VERSION "1.0"

NS_ :

BS_:

BU_: PC DASHBOARD PDM_FRONT PDM_REAR KEYPAD

BO_ 1536 CMD_BROADCAST: 8 PC
 SG_ MsgType M : 0|8@1+ (1,0) [0|255] "" Vector__XXX

BO_ 1605 CMD_DASHBOARD: 8 PC
 SG_ MsgType M : 0|8@1+ (1,0) [0|255] "" DASHBOARD
 SG_ FileSize m16 : 8|32@1+ (1,0) [0|4294967295] "bytes" DASHBOARD
 SG_ FileCrc32 m17 : 8|32@1+ (1,0) [0|4294967295] "" DASHBOARD
 SG_ BlockNumber m18 : 8|16@1+ (1,0) [0|65535] "" DASHBOARD
 SG_ BlockLength m18 : 24|16@1+ (1,0) [0|65535] "bytes" DASHBOARD

BO_ 1733 REPLY_DASHBOARD: 8 DASHBOARD
 SG_ MsgType M : 0|8@1+ (1,0) [0|255] "" PC
 SG_ HbState m128 : 8|8@1+ (1,0) [0|255] "" PC
 SG_ HbFwMajor m128 : 16|8@1+ (1,0) [0|255] "" PC
 SG_ HbFwMinor m128 : 24|8@1+ (1,0) [0|255] "" PC
 SG_ HbFwPatch m128 : 32|8@1+ (1,0) [0|255] "" PC
 SG_ ChipType m129 : 8|8@1+ (1,0) [0|255] "" PC
 SG_ HwRevision m129 : 16|8@1+ (1,0) [0|255] "" PC
 SG_ FwMajor m129 : 24|8@1+ (1,0) [0|255] "" PC
 SG_ FwMinor m129 : 32|8@1+ (1,0) [0|255] "" PC
 SG_ FwPatch m129 : 40|8@1+ (1,0) [0|255] "" PC
 SG_ Uid0 m130 : 8|8@1+ (1,0) [0|255] "" PC
 SG_ Uid1 m130 : 16|8@1+ (1,0) [0|255] "" PC
 SG_ Uid2 m130 : 24|8@1+ (1,0) [0|255] "" PC
 SG_ Uid3 m130 : 32|8@1+ (1,0) [0|255] "" PC
 SG_ Uid4 m130 : 40|8@1+ (1,0) [0|255] "" PC
 SG_ Uid5 m130 : 48|8@1+ (1,0) [0|255] "" PC
 SG_ BeginStatus m144 : 8|8@1+ (1,0) [0|255] "" PC
 SG_ AckBlock m146 : 8|16@1+ (1,0) [0|65535] "" PC
 SG_ AckStatus m146 : 24|8@1+ (1,0) [0|255] "" PC
 SG_ FinishStatus m147 : 8|8@1+ (1,0) [0|255] "" PC
 SG_ BootStatus m149 : 8|8@1+ (1,0) [0|255] "" PC

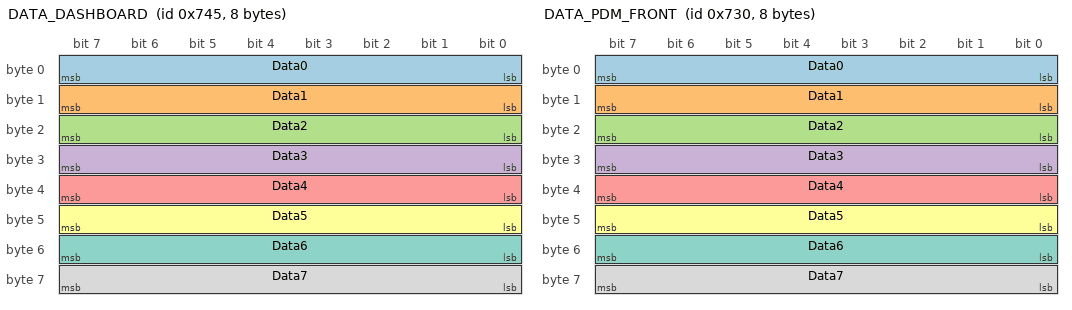
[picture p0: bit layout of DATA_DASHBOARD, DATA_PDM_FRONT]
BO_ 1861 DATA_DASHBOARD: 8 PC
 SG_ Data0 : 0|8@1+ (1,0) [0|255] "" DASHBOARD
 SG_ Data1 : 8|8@1+ (1,0) [0|255] "" DASHBOARD
 SG_ Data2 : 16|8@1+ (1,0) [0|255] "" DASHBOARD
 SG_ Data3 : 24|8@1+ (1,0) [0|255] "" DASHBOARD
 SG_ Data4 : 32|8@1+ (1,0) [0|255] "" DASHBOARD
 SG_ Data5 : 40|8@1+ (1,0) [0|255] "" DASHBOARD
 SG_ Data6 : 48|8@1+ (1,0) [0|255] "" DASHBOARD
 SG_ Data7 : 56|8@1+ (1,0) [0|255] "" DASHBOARD

BO_ 1584 CMD_PDM_FRONT: 8 PC
 SG_ MsgType M : 0|8@1+ (1,0) [0|255] "" PDM_FRONT
 SG_ FileSize m16 : 8|32@1+ (1,0) [0|4294967295] "bytes" PDM_FRONT
 SG_ FileCrc32 m17 : 8|32@1+ (1,0) [0|4294967295] "" PDM_FRONT
 SG_ BlockNumber m18 : 8|16@1+ (1,0) [0|65535] "" PDM_FRONT
 SG_ BlockLength m18 : 24|16@1+ (1,0) [0|65535] "bytes" PDM_FRONT

BO_ 1712 REPLY_PDM_FRONT: 8 PDM_FRONT
 SG_ MsgType M : 0|8@1+ (1,0) [0|255] "" PC
 SG_ HbState m128 : 8|8@1+ (1,0) [0|255] "" PC
 SG_ HbFwMajor m128 : 16|8@1+ (1,0) [0|255] "" PC
 SG_ HbFwMinor m128 : 24|8@1+ (1,0) [0|255] "" PC
 SG_ HbFwPatch m128 : 32|8@1+ (1,0) [0|255] "" PC
 SG_ ChipType m129 : 8|8@1+ (1,0) [0|255] "" PC
 SG_ HwRevision m129 : 16|8@1+ (1,0) [0|255] "" PC
 SG_ FwMajor m129 : 24|8@1+ (1,0) [0|255] "" PC
 SG_ FwMinor m129 : 32|8@1+ (1,0) [0|255] "" PC
 SG_ FwPatch m129 : 40|8@1+ (1,0) [0|255] "" PC
 SG_ Uid0 m130 : 8|8@1+ (1,0) [0|255] "" PC
 SG_ Uid1 m130 : 16|8@1+ (1,0) [0|255] "" PC
 SG_ Uid2 m130 : 24|8@1+ (1,0) [0|255] "" PC
 SG_ Uid3 m130 : 32|8@1+ (1,0) [0|255] "" PC
 SG_ Uid4 m130 : 40|8@1+ (1,0) [0|255] "" PC
 SG_ Uid5 m130 : 48|8@1+ (1,0) [0|255] "" PC
 SG_ BeginStatus m144 : 8|8@1+ (1,0) [0|255] "" PC
 SG_ AckBlock m146 : 8|16@1+ (1,0) [0|65535] "" PC
 SG_ AckStatus m146 : 24|8@1+ (1,0) [0|255] "" PC
 SG_ FinishStatus m147 : 8|8@1+ (1,0) [0|255] "" PC
 SG_ BootStatus m149 : 8|8@1+ (1,0) [0|255] "" PC

BO_ 1840 DATA_PDM_FRONT: 8 PC
 SG_ Data0 : 0|8@1+ (1,0) [0|255] "" PDM_FRONT
 SG_ Data1 : 8|8@1+ (1,0) [0|255] "" PDM_FRONT
 SG_ Data2 : 16|8@1+ (1,0) [0|255] "" PDM_FRONT
 SG_ Data3 : 24|8@1+ (1,0) [0|255] "" PDM_FRONT
 SG_ Data4 : 32|8@1+ (1,0) [0|255] "" PDM_FRONT
 SG_ Data5 : 40|8@1+ (1,0) [0|255] "" PDM_FRONT
 SG_ Data6 : 48|8@1+ (1,0) [0|255] "" PDM_FRONT
 SG_ Data7 : 56|8@1+ (1,0) [0|255] "" PDM_FRONT

BO_ 1585 CMD_PDM_REAR: 8 PC
 SG_ MsgType M : 0|8@1+ (1,0) [0|255] "" PDM_REAR
 SG_ FileSize m16 : 8|32@1+ (1,0) [0|4294967295] "bytes" PDM_REAR
 SG_ FileCrc32 m17 : 8|32@1+ (1,0) [0|4294967295] "" PDM_REAR
 SG_ BlockNumber m18 : 8|16@1+ (1,0) [0|65535] "" PDM_REAR
 SG_ BlockLength m18 : 24|16@1+ (1,0) [0|65535] "bytes" PDM_REAR

BO_ 1713 REPLY_PDM_REAR: 8 PDM_REAR
 SG_ MsgType M : 0|8@1+ (1,0) [0|255] "" PC
 SG_ HbState m128 : 8|8@1+ (1,0) [0|255] "" PC
 SG_ HbFwMajor m128 : 16|8@1+ (1,0) [0|255] "" PC
 SG_ HbFwMinor m128 : 24|8@1+ (1,0) [0|255] "" PC
 SG_ HbFwPatch m128 : 32|8@1+ (1,0) [0|255] "" PC
 SG_ ChipType m129 : 8|8@1+ (1,0) [0|255] "" PC
 SG_ HwRevision m129 : 16|8@1+ (1,0) [0|255] "" PC
 SG_ FwMajor m129 : 24|8@1+ (1,0) [0|255] "" PC
 SG_ FwMinor m129 : 32|8@1+ (1,0) [0|255] "" PC
 SG_ FwPatch m129 : 40|8@1+ (1,0) [0|255] "" PC
 SG_ Uid0 m130 : 8|8@1+ (1,0) [0|255] "" PC
 SG_ Uid1 m130 : 16|8@1+ (1,0) [0|255] "" PC
 SG_ Uid2 m130 : 24|8@1+ (1,0) [0|255] "" PC
 SG_ Uid3 m130 : 32|8@1+ (1,0) [0|255] "" PC
 SG_ Uid4 m130 : 40|8@1+ (1,0) [0|255] "" PC
 SG_ Uid5 m130 : 48|8@1+ (1,0) [0|255] "" PC
 SG_ BeginStatus m144 : 8|8@1+ (1,0) [0|255] "" PC
 SG_ AckBlock m146 : 8|16@1+ (1,0) [0|65535] "" PC
 SG_ AckStatus m146 : 24|8@1+ (1,0) [0|255] "" PC
 SG_ FinishStatus m147 : 8|8@1+ (1,0) [0|255] "" PC
 SG_ BootStatus m149 : 8|8@1+ (1,0) [0|255] "" PC

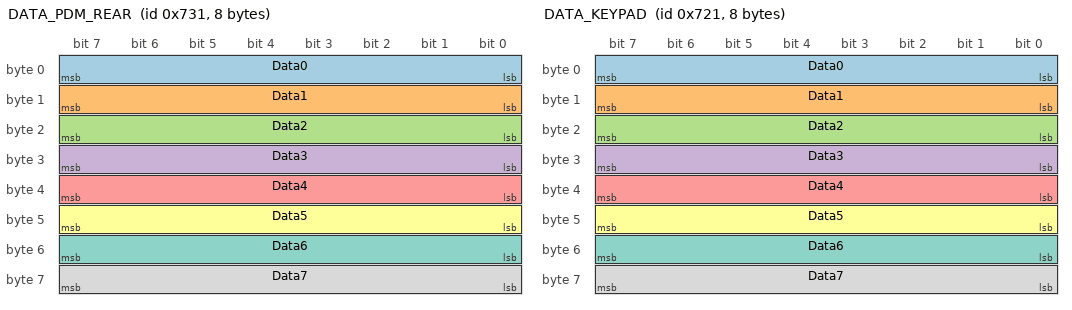
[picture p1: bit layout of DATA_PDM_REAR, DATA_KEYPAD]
BO_ 1841 DATA_PDM_REAR: 8 PC
 SG_ Data0 : 0|8@1+ (1,0) [0|255] "" PDM_REAR
 SG_ Data1 : 8|8@1+ (1,0) [0|255] "" PDM_REAR
 SG_ Data2 : 16|8@1+ (1,0) [0|255] "" PDM_REAR
 SG_ Data3 : 24|8@1+ (1,0) [0|255] "" PDM_REAR
 SG_ Data4 : 32|8@1+ (1,0) [0|255] "" PDM_REAR
 SG_ Data5 : 40|8@1+ (1,0) [0|255] "" PDM_REAR
 SG_ Data6 : 48|8@1+ (1,0) [0|255] "" PDM_REAR
 SG_ Data7 : 56|8@1+ (1,0) [0|255] "" PDM_REAR

BO_ 1569 CMD_KEYPAD: 8 PC
 SG_ MsgType M : 0|8@1+ (1,0) [0|255] "" KEYPAD
 SG_ FileSize m16 : 8|32@1+ (1,0) [0|4294967295] "bytes" KEYPAD
 SG_ FileCrc32 m17 : 8|32@1+ (1,0) [0|4294967295] "" KEYPAD
 SG_ BlockNumber m18 : 8|16@1+ (1,0) [0|65535] "" KEYPAD
 SG_ BlockLength m18 : 24|16@1+ (1,0) [0|65535] "bytes" KEYPAD

BO_ 1697 REPLY_KEYPAD: 8 KEYPAD
 SG_ MsgType M : 0|8@1+ (1,0) [0|255] "" PC
 SG_ HbState m128 : 8|8@1+ (1,0) [0|255] "" PC
 SG_ HbFwMajor m128 : 16|8@1+ (1,0) [0|255] "" PC
 SG_ HbFwMinor m128 : 24|8@1+ (1,0) [0|255] "" PC
 SG_ HbFwPatch m128 : 32|8@1+ (1,0) [0|255] "" PC
 SG_ ChipType m129 : 8|8@1+ (1,0) [0|255] "" PC
 SG_ HwRevision m129 : 16|8@1+ (1,0) [0|255] "" PC
 SG_ FwMajor m129 : 24|8@1+ (1,0) [0|255] "" PC
 SG_ FwMinor m129 : 32|8@1+ (1,0) [0|255] "" PC
 SG_ FwPatch m129 : 40|8@1+ (1,0) [0|255] "" PC
 SG_ Uid0 m130 : 8|8@1+ (1,0) [0|255] "" PC
 SG_ Uid1 m130 : 16|8@1+ (1,0) [0|255] "" PC
 SG_ Uid2 m130 : 24|8@1+ (1,0) [0|255] "" PC
 SG_ Uid3 m130 : 32|8@1+ (1,0) [0|255] "" PC
 SG_ Uid4 m130 : 40|8@1+ (1,0) [0|255] "" PC
 SG_ Uid5 m130 : 48|8@1+ (1,0) [0|255] "" PC
 SG_ BeginStatus m144 : 8|8@1+ (1,0) [0|255] "" PC
 SG_ AckBlock m146 : 8|16@1+ (1,0) [0|65535] "" PC
 SG_ AckStatus m146 : 24|8@1+ (1,0) [0|255] "" PC
 SG_ FinishStatus m147 : 8|8@1+ (1,0) [0|255] "" PC
 SG_ BootStatus m149 : 8|8@1+ (1,0) [0|255] "" PC

BO_ 1825 DATA_KEYPAD: 8 PC
 SG_ Data0 : 0|8@1+ (1,0) [0|255] "" KEYPAD
 SG_ Data1 : 8|8@1+ (1,0) [0|255] "" KEYPAD
 SG_ Data2 : 16|8@1+ (1,0) [0|255] "" KEYPAD
 SG_ Data3 : 24|8@1+ (1,0) [0|255] "" KEYPAD
 SG_ Data4 : 32|8@1+ (1,0) [0|255] "" KEYPAD
 SG_ Data5 : 40|8@1+ (1,0) [0|255] "" KEYPAD
 SG_ Data6 : 48|8@1+ (1,0) [0|255] "" KEYPAD
 SG_ Data7 : 56|8@1+ (1,0) [0|255] "" KEYPAD

CM_ BO_ 1536 "PC to all boards. Only SCAN (MsgType 1) is accepted in broadcast.";
CM_ BO_ 1605 "PC to Dashboard (ESP32-S3): commands. MsgType 1 SCAN, 16 BEGIN, 17 CRC, 18 BLOCK_END, 19 FINISH, 20 ABORT, 21 ENTER_BOOT.";
CM_ BO_ 1733 "Dashboard (ESP32-S3) to PC: heartbeat, scan answers (INFO_A, INFO_B) and update answers.";
CM_ SG_ 1733 HwRevision "Hardware revision as an ASCII letter (65 = A, 66 = B).";
CM_ SG_ 1733 AckBlock "Number of the block confirmed (or refused) by the board.";
CM_ BO_ 1861 "File data for Dashboard (ESP32-S3): 8 raw bytes per frame, 32 frames per block of 256 bytes.";
CM_ BO_ 1584 "PC to PDM Anteriore (STM32): commands. MsgType 1 SCAN, 16 BEGIN, 17 CRC, 18 BLOCK_END, 19 FINISH, 20 ABORT, 21 ENTER_BOOT.";
CM_ BO_ 1712 "PDM Anteriore (STM32) to PC: heartbeat, scan answers (INFO_A, INFO_B) and update answers.";
CM_ SG_ 1712 HwRevision "Hardware revision as an ASCII letter (65 = A, 66 = B).";
CM_ SG_ 1712 AckBlock "Number of the block confirmed (or refused) by the board.";
CM_ BO_ 1840 "File data for PDM Anteriore (STM32): 8 raw bytes per frame, 32 frames per block of 256 bytes.";
CM_ BO_ 1585 "PC to PDM Posteriore (STM32): commands. MsgType 1 SCAN, 16 BEGIN, 17 CRC, 18 BLOCK_END, 19 FINISH, 20 ABORT, 21 ENTER_BOOT.";
CM_ BO_ 1713 "PDM Posteriore (STM32) to PC: heartbeat, scan answers (INFO_A, INFO_B) and update answers.";
CM_ SG_ 1713 HwRevision "Hardware revision as an ASCII letter (65 = A, 66 = B).";
CM_ SG_ 1713 AckBlock "Number of the block confirmed (or refused) by the board.";
CM_ BO_ 1841 "File data for PDM Posteriore (STM32): 8 raw bytes per frame, 32 frames per block of 256 bytes.";
CM_ BO_ 1569 "PC to Tastierino: commands. MsgType 1 SCAN, 16 BEGIN, 17 CRC, 18 BLOCK_END, 19 FINISH, 20 ABORT, 21 ENTER_BOOT.";
CM_ BO_ 1697 "Tastierino to PC: heartbeat, scan answers (INFO_A, INFO_B) and update answers.";
CM_ SG_ 1697 HwRevision "Hardware revision as an ASCII letter (65 = A, 66 = B).";
CM_ SG_ 1697 AckBlock "Number of the block confirmed (or refused) by the board.";
CM_ BO_ 1825 "File data for Tastierino: 8 raw bytes per frame, 32 frames per block of 256 bytes.";

VAL_ 1536 MsgType 1 "SCAN" ;
VAL_ 1605 MsgType 1 "SCAN" 16 "BEGIN" 17 "CRC" 18 "BLOCK_END" 19 "FINISH" 20 "ABORT" 21 "ENTER_BOOT" ;
VAL_ 1733 MsgType 128 "HEARTBEAT" 129 "INFO_A" 130 "INFO_B" 144 "BEGIN_ACK" 146 "BLOCK_ACK" 147 "FINISH_ACK" 149 "BOOT_ACK" ;
VAL_ 1733 HbState 0 "APPLICATION" 1 "UPDATE_IN_PROGRESS" ;
VAL_ 1733 ChipType 1 "ESP32-S3" 2 "STM32" ;
VAL_ 1733 BeginStatus 0 "OK" 1 "RETRY" 2 "TOO_BIG" 3 "BUSY" 4 "FLASH_ERROR" 5 "INVALID" ;
VAL_ 1733 AckStatus 0 "OK" 1 "RETRY" 2 "TOO_BIG" 3 "BUSY" 4 "FLASH_ERROR" 5 "INVALID" ;
VAL_ 1733 FinishStatus 0 "OK" 1 "RETRY" 2 "TOO_BIG" 3 "BUSY" 4 "FLASH_ERROR" 5 "INVALID" ;
VAL_ 1733 BootStatus 0 "OK" 1 "RETRY" 2 "TOO_BIG" 3 "BUSY" 4 "FLASH_ERROR" 5 "INVALID" ;
VAL_ 1584 MsgType 1 "SCAN" 16 "BEGIN" 17 "CRC" 18 "BLOCK_END" 19 "FINISH" 20 "ABORT" 21 "ENTER_BOOT" ;
VAL_ 1712 MsgType 128 "HEARTBEAT" 129 "INFO_A" 130 "INFO_B" 144 "BEGIN_ACK" 146 "BLOCK_ACK" 147 "FINISH_ACK" 149 "BOOT_ACK" ;
VAL_ 1712 HbState 0 "APPLICATION" 1 "UPDATE_IN_PROGRESS" ;
VAL_ 1712 ChipType 1 "ESP32-S3" 2 "STM32" ;
VAL_ 1712 BeginStatus 0 "OK" 1 "RETRY" 2 "TOO_BIG" 3 "BUSY" 4 "FLASH_ERROR" 5 "INVALID" ;
VAL_ 1712 AckStatus 0 "OK" 1 "RETRY" 2 "TOO_BIG" 3 "BUSY" 4 "FLASH_ERROR" 5 "INVALID" ;
VAL_ 1712 FinishStatus 0 "OK" 1 "RETRY" 2 "TOO_BIG" 3 "BUSY" 4 "FLASH_ERROR" 5 "INVALID" ;
VAL_ 1712 BootStatus 0 "OK" 1 "RETRY" 2 "TOO_BIG" 3 "BUSY" 4 "FLASH_ERROR" 5 "INVALID" ;
VAL_ 1585 MsgType 1 "SCAN" 16 "BEGIN" 17 "CRC" 18 "BLOCK_END" 19 "FINISH" 20 "ABORT" 21 "ENTER_BOOT" ;
VAL_ 1713 MsgType 128 "HEARTBEAT" 129 "INFO_A" 130 "INFO_B" 144 "BEGIN_ACK" 146 "BLOCK_ACK" 147 "FINISH_ACK" 149 "BOOT_ACK" ;
VAL_ 1713 HbState 0 "APPLICATION" 1 "UPDATE_IN_PROGRESS" ;
VAL_ 1713 ChipType 1 "ESP32-S3" 2 "STM32" ;
VAL_ 1713 BeginStatus 0 "OK" 1 "RETRY" 2 "TOO_BIG" 3 "BUSY" 4 "FLASH_ERROR" 5 "INVALID" ;
VAL_ 1713 AckStatus 0 "OK" 1 "RETRY" 2 "TOO_BIG" 3 "BUSY" 4 "FLASH_ERROR" 5 "INVALID" ;
VAL_ 1713 FinishStatus 0 "OK" 1 "RETRY" 2 "TOO_BIG" 3 "BUSY" 4 "FLASH_ERROR" 5 "INVALID" ;
VAL_ 1713 BootStatus 0 "OK" 1 "RETRY" 2 "TOO_BIG" 3 "BUSY" 4 "FLASH_ERROR" 5 "INVALID" ;
VAL_ 1569 MsgType 1 "SCAN" 16 "BEGIN" 17 "CRC" 18 "BLOCK_END" 19 "FINISH" 20 "ABORT" 21 "ENTER_BOOT" ;
VAL_ 1697 MsgType 128 "HEARTBEAT" 129 "INFO_A" 130 "INFO_B" 144 "BEGIN_ACK" 146 "BLOCK_ACK" 147 "FINISH_ACK" 149 "BOOT_ACK" ;
VAL_ 1697 HbState 0 "APPLICATION" 1 "UPDATE_IN_PROGRESS" ;
VAL_ 1697 ChipType 1 "ESP32-S3" 2 "STM32" ;
VAL_ 1697 BeginStatus 0 "OK" 1 "RETRY" 2 "TOO_BIG" 3 "BUSY" 4 "FLASH_ERROR" 5 "INVALID" ;
VAL_ 1697 AckStatus 0 "OK" 1 "RETRY" 2 "TOO_BIG" 3 "BUSY" 4 "FLASH_ERROR" 5 "INVALID" ;
VAL_ 1697 FinishStatus 0 "OK" 1 "RETRY" 2 "TOO_BIG" 3 "BUSY" 4 "FLASH_ERROR" 5 "INVALID" ;
VAL_ 1697 BootStatus 0 "OK" 1 "RETRY" 2 "TOO_BIG" 3 "BUSY" 4 "FLASH_ERROR" 5 "INVALID" ;
